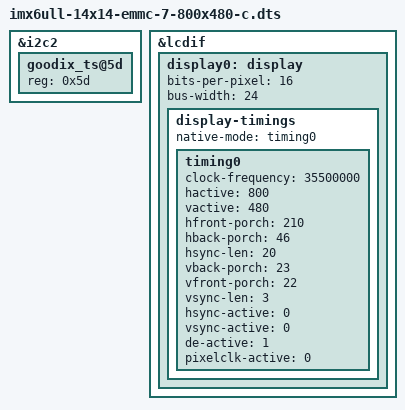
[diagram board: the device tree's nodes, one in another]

#include "imx6ull-14x14-evk-emmc.dts"

&i2c2 {
	goodix_ts@5d {
		reg = <0x5d>;
	};
};

&lcdif {
	display0: display {
		bits-per-pixel = <16>;
		bus-width = <24>;

		display-timings {
			native-mode = <&timing0>;
			timing0: timing0 {
			clock-frequency = <35500000>;
			hactive = <800>;
			vactive = <480>;
			hfront-porch = <210>;
			hback-porch = <46>;
			hsync-len = <20>;
			vback-porch = <23>;
			vfront-porch = <22>;
			vsync-len = <3>;

			hsync-active = <0>;
			vsync-active = <0>;
			de-active = <1>;
			pixelclk-active = <0>;
			};
		};
	};
};
